# RTS591x register map
Vendor: Realtek Semiconductor Corp.; Series: RTS591x Series; File version: 1.0
CPU: ARMV8MML r0p0, little endian, MPU, FPU, VTOR, 3 interrupt priority bits, 4 SAU regions
Registers are 32-bit, read-write, reset 0x0 unless marked. A register's access mark holds for its fields unless they carry their own. Offsets are from the block's base; [hi:lo] are bit positions.

## I3C0 — I3C Controller
Base 0x4000E000
Same registers: I3C1 0x400B0000
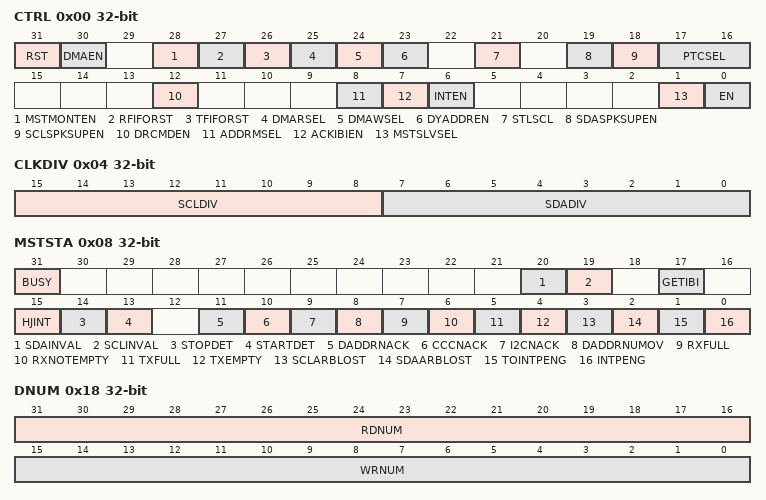
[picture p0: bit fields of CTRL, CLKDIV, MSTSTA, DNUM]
0x00 CTRL — CONTROL REGISTER
  [31] RST — Soft Reset
    0=RESET (Reset I3C controller); 1=DO_NOTHING
  [30] DMAEN — DMA Enable
    0=DISABLE (Disable DMA); 1=ENABLE (Enable DMA)
  [28] MSTMONTEN — Master Monitor Enable
    0=DISABLE (Disable master monitor function); 1=ENABLE (Enable master monitor function)
  [27] RFIFORST — Rx FIFO Reset
    0=RESET (Reset Rx FIFO); 1=DO_NOTHING
  [26] TFIFORST — Tx FIFO Reset
    0=RESET (Reset Tx FIFO); 1=DO_NOTHING
  [25] DMARSEL — DMA Read Size Select
    0=BY_DNUM (Read data size depends on DNUM register); 1=BY_DMA_BLKTS (Read data size depends on DMA block transfer size)
  [24] DMAWSEL — DMA Write Size Select
    0=BY_DNUM (Write data size depends on DNUM register); 1=BY_DMA_BLKTS (Write data size depends on DMA block transfer size)
  [23] DYADDREN — Dynamic Address Assign Enable
    0=DISABLE (Disable dynamic address assign); 1=ENABLE (Enable dynamic address assign)
  [21] STLSCL — Stall SCL
    0=NOT_STALL (Not stall SCL at low level at T-bit/ACK); 1=STALL (Stall SCL at low level at T-bit/ACK)
  [19] SDASPKSUPEN — SDA Spike Suppression Enable
    0=DISABLE (Disable SDA spike suppression); 1=ENABLE (Enable SDA spike suppression)
  [18] SCLSPKSUPEN — SCL Spike Suppression Enable
    0=DISABLE (Disable SCL spike suppression); 1=ENABLE (Enable SCL spike suppression)
  [17:16] PTCSEL — Protocol Select
    0=I2C (I2C mode); 1=SDR (I3C SDR mode)
  [12] DRCMDEN — Direct Command Enable
    0=DISABLE (Disable direct command); 1=ENABLE (Enable direct command)
  [8] ADDRMSEL — Address Mode Select
    0=10_BIT (10-bit address mode); 1=7_BIT (7-bit address mode)
  [7] ACKIBIEN — Ack IBI Enable
    0=DISABLE (Disable Ack IBI); 1=ENABLE (Enable Ack IBI)
  [6] INTEN — Interrupt Enable
    0=DISABLE (Disable interrupt); 1=ENABLE (Enable interrupt)
  [1] MSTSLVSEL — Master Slave Select
    0=SLAVE (Using slave mode); 1=MASTER (Using master mode)
  [0] EN — Enable
    0=DISABLE (Disable I3C controller); 1=ENABLE (Enable I3C controller)
0x04 CLKDIV — CLOCK DIVIDER REGISTER
  [15:8] SCLDIV — SCL Divider
  [7:0] SDADIV — SDA Divider
0x08 MSTSTA — MASTER STATUS REGISTER
  [31] BUSY — Bus Busy
  [20] SDAINVAL — Sda Input Value
  [19] SCLINVAL — Scl Input Value
  [17] GETIBI — Get In Band Interrupt
  [15] HJINT — Hot Join Interrupt
  [14] STOPDET — Stop Condition Detected
  [13] STARTDET — Start Condition Detected
  [11] DADDRNACK — Dynamic Address Assigned NACK
  [10] CCCNACK — Common Command Code NACK
  [9] I2CNACK
  [8] DADDRNUMOV — Dynamic Address Number Overflow
  [7] RXFULL — Rx FIFO Full
  [6] RXNOTEMPTY — Rx FIFO Not Empty
  [5] TXFULL — Tx FIFO Full
  [4] TXEMPTY — Tx FIFO Empty
  [3] SCLARBLOST — SCL Arbitration Lost
  [2] SDAARBLOST — SDA Arbitration Lost
  [1] TOINTPENG — Timeout Interrupt Pending
  [0] INTPENG — Interrupt Pending
0x0C TO — TIME OUT REGISTER
  [23:0] TOCNT — Timeout Counter
0x10 DBUF — DATA BUFFER REGISTER
0x14 SLVADDR — SLAVE ADDRESS REGISTER
  [15:0] ADDR — Slave Address
0x18 DNUM — DATA NUMBER REGISTER
  [31:16] RDNUM — Data Number to Read
  [15:0] WRNUM — Data Number to Write
0x1C DIRCMD — DIRECT COMMAND REGISTER
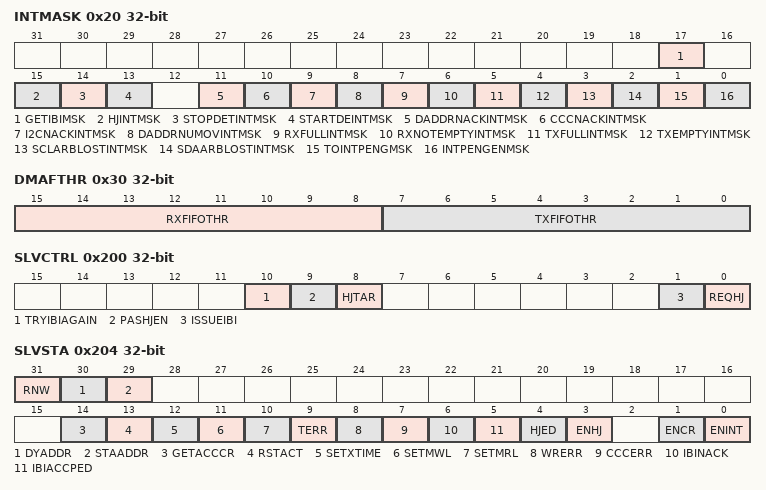
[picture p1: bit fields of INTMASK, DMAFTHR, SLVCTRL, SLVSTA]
0x20 INTMASK — INTERRUPT MASK REGISTER
  [17] GETIBIMSK — In Band Interrupt Mask Bit
  [15] HJINTMSK — Hot Join Interrupt Mask Bit
  [14] STOPDETINTMSK — Stop Condition Detected Interrupt Mask Bit
  [13] STARTDEINTMSK — Start Condition Detected Interrupt Mask Bit
  [11] DADDRNACKINTMSK — Dynamic Address Assigned NACK Interrupt Mask Bit
  [10] CCCNACKINTMSK — Common Command Code NACK Interrupt Mask Bit
  [9] I2CNACKINTMSK — I2C NACK Interrupt Mask Bit
  [8] DADDRNUMOVINTMSK — Dynamic Address Number Overflow Interrupt Mask Bit
  [7] RXFULLINTMSK — Rx FIFO Full Interrupt Mask Bit
  [6] RXNOTEMPTYINTMSK — Rx FIFO Not Empty Interrupt Mask Bit
  [5] TXFULLINTMSK — Tx FIFO Full Interrupt Mask Bit
  [4] TXEMPTYINTMSK — Tx FIFO Empty Interrupt Mask Bit
  [3] SCLARBLOSTINTMSK — SCL Arbitration Lost Interrupt Mask Bit
  [2] SDAARBLOSTINTMSK — SDA Arbitration Lost Interrupt Mask Bit
  [1] TOINTPENGMSK — Timeout Interrupt Pending Interrupt Mask Bit
  [0] INTPENGENMSK — Interrupt Pending Mask Bit
0x30 DMAFTHR — DMA FIFO THRESHOLD
  [15:8] RXFIFOTHR — RX FIFO Threshold
  [7:0] TXFIFOTHR — TX FIFO Threshold
0x34 SPKCNT — SPIKE COUNTER REGISTER
  [7:0] CNT — Spike Count
0x40 TXFRMLEN — TX FIFO REMAIN LENGTH REGISTER
0x44 TXFLEN — TX FIFO LENGTH REGISTER
0x48 RXFRMLEN — RX FIFO REMAIN LENGTH REGISTER
0x4C RXFLEN — RX FIFO LENGTH REGISTER
0x50 DYNADDR — DYNAMIC ADDRESS REGISTER
  [6:0] ADDR — Dynamci Address
0x200 SLVCTRL — SLAVE CONTROL REGISTER
  [10] TRYIBIAGAIN — Slave Choose To Try IBI Again When Receive NACK or Arbtion Lost
  [9] PASHJEN — Enable Slave To Issue Passive Hot-Join Or Not
  [8] HJTAR — Hot-Hoined Target, Can Issue A Hot-Join
  [1] ISSUEIBI — Slave Issues IBI
  [0] REQHJ — Slave Request Hot-Join
0x204 SLVSTA — SLAVE STATUS REGISTER
  [31] RNW — Slave Read Write Status
  [30] DYADDR ro — Slave Dynamic Address Assigned
  [29] STAADDR ro — Slave Static Address Assigned
  [14] GETACCCR ro — Slave Get Accept Controller Role
  [13] RSTACT ro — Slave Target Reset Action
  [12] SETXTIME — Slave Set Exchange Timing Information
  [11] SETMWL — Slave Set Maximum Write Length
  [10] SETMRL — Slave Set Maximum Read Length
  [9] TERR ro — Slave Tbit Error Interrupt
  [8] WRERR ro — Slave Write Length More Than MWL Error Interrupt
  [7] CCCERR ro — Slave CCC Error
  [6] IBINACK ro — In Band Interrupt NACK
  [5] IBIACCPED ro — In Band Interrupt Accepted
  [4] HJED ro — HOT-JOINED
  [3] ENHJ — Enable Hot-Join
  [1] ENCR — Enable CRC
  [0] ENINT — Enable Interrupt
0x220 SLVUIDL — SLAVE UNIQUE ID LOW REGISTER
0x224 SLVUIDH — SLAVE UNIQUE ID HIGH REGISTER
0x228 SLVBCR — SLAVE BUS CHARACTERISTIC REGISTER
  [7:0] BCR — Bus Characteristic
0x22C SLVDCR — SLAVE DEVICE CHARACTERISTIC REGISTER
  [7:0] DCR — Device Characteristic
0x230 SLVMDB — SLAVE MANDATORY DATA BYTE REGISTER
  [7:0] MDB — Mandatory Data Byte
0x234 SLVSETXTIME — SLAVE SETXTIME BYTE REGISTER
  [7:0] SETXTIME
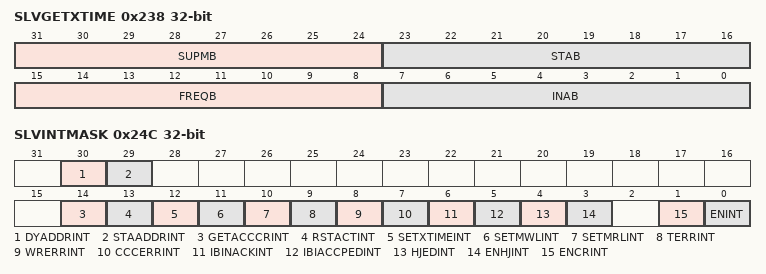
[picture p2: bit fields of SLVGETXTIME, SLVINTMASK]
0x238 SLVGETXTIME — SLAVE GETXTIME BYTE REGISTER
  [31:24] SUPMB — Supported Mode Byte
  [23:16] STAB — State Byte
  [15:8] FREQB — Frequency Byte
  [7:0] INAB — Inaccuracy Byte
0x23C SLVRSTACT — SLAVE RSTACT REGISTER
  [7:0] RSTACT — The Data Follows The RSTACT CCC
0x240 SLVMWL — SLAVE MWL REGISTER
  [15:0] MWL — Max Write Length
0x244 SLVMRL — SLAVE MRL REGISTER
  [15:0] MRL — Max Read Length
0x248 SLVGETSTATUS — SLAVE GETSTATUS REGISTER
  [15:0] STSDATA
0x24C SLVINTMASK — SLAVE INTERRUPT MASK REGISTER
  [30] DYADDRINT — Dynamic Address Assigned Interrupt Mask
  [29] STAADDRINT — Static Address Assigned Interrupt Mask
  [14] GETACCCRINT — Get Accept Controller Role Interrupt Mask
  [13] RSTACTINT — Target Reset Action Interrupt Mask
  [12] SETXTIMEINT — Set Exchange Timing Information Interrupt Mask
  [11] SETMWLINT — Set Maximum Write Length Interrupt Mask
  [10] SETMRLINT — Set Maximum Read Length Interrupt Mask
  [9] TERRINT — Slave Tbit Error Interrupt Mask
  [8] WRERRINT — Slave Write Length More Than MWL Error Interrupt Mask
  [7] CCCERRINT — CCC Error Interrupt Mask
  [6] IBINACKINT — In Band Interrupt NACK Interrupt Mask
  [5] IBIACCPEDINT — In Band Interrupt Accepted Interrupt Mask
  [4] HJEDINT — HOT-JOINED Interrupt Mask
  [3] ENHJINT — ENHJ Interrupt Mask
  [1] ENCRINT — ENCR Interrupt Mask
  [0] ENINT — ENINT Interrupt Mask
